# MB9BF56xM register map
Vendor: Cypress; File version: 2.1
CPU: CM4 r0p1, little endian, MPU, FPU, 4 interrupt priority bits
Registers are 32-bit, read-write, reset 0x0 unless marked. A register's access mark holds for its fields unless they carry their own. Offsets are from the block's base; [hi:lo] are bit positions; {n}, {i} and the like mark numbered series; 'fields as' and 'values as' point back to an identical list.

## CAN0 — CAN0 Registers
Base 0x40062000
Same registers: CAN1 0x40063000
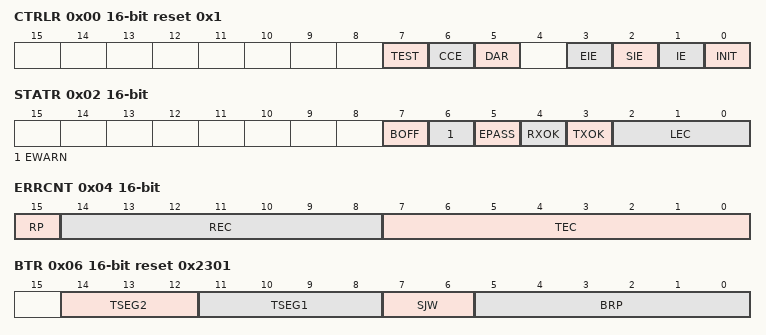
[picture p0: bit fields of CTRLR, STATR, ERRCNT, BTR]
0x00 CTRLR 16-bit reset 0x1 — CAN Control Register [BHW]
  [7] TEST — Test mode enable bit
  [6] CCE — Bit Timing Register write enable bit
  [5] DAR — Automatic retransmission disable bit
  [3] EIE — Error interrupt code enable bit
  [2] SIE — Status interrupt code enable bit
  [1] IE — Interrupt enable bit
  [0] INIT — Initialization bit
0x02 STATR 16-bit — CAN Status Register [BHW]
  [7] BOFF ro — Busoff bit
  [6] EWARN ro — Warning bit
  [5] EPASS ro — Error passive bit
  [4] RXOK — Successful message reception bit
  [3] TXOK — Successful message transmission bit
  [2:0] LEC — Last error code bits
0x04 ERRCNT 16-bit ro — CAN Error Counter [BHW]
  [15] RP — Receive error passive indication
  [14:8] REC — Receive error counter
  [7:0] TEC — Send error counter
0x06 BTR 16-bit reset 0x2301 — CAN Bit Timing Register [BHW]
  [14:12] TSEG2 — Time segment 2 setting bits
  [11:8] TSEG1 — Time segment 1 setting bits
  [7:6] SJW — Resynchronization jump width setting bits
  [5:0] BRP — Baud rate prescaler setting bits
0x08 INTR 16-bit ro — CAN Interrupt Register [BHW]
  [15:0] INTID — Interrupt Code
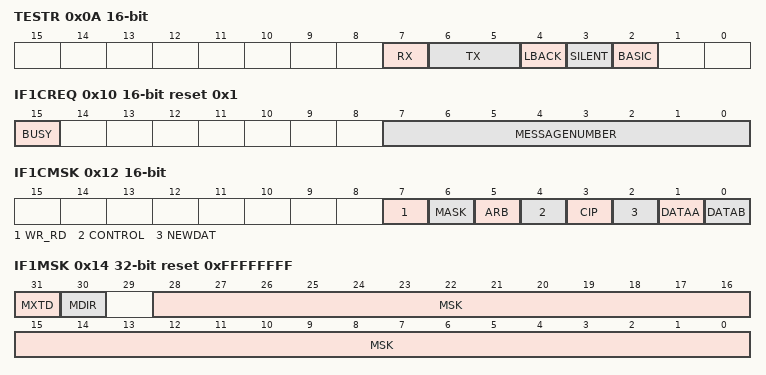
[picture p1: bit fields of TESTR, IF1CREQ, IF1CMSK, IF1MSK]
0x0A TESTR 16-bit — CAN Test Register [BHW]
  [7] RX ro — Rx pin monitor bit
  [6:5] TX — TX pin control bit
  [4] LBACK — Loop back mode
  [3] SILENT — Silent mode
  [2] BASIC — Basic mode
0x0C BRPER 16-bit — CAN Prescaler Extension Register [BHW]
  [3:0] BRPE — Baud rate prescaler extension bit
0x10 IF1CREQ 16-bit reset 0x1 — IF1 Command Request Register [BHW]
  [15] BUSY — Busy flag bit
  [7:0] MESSAGENUMBER
0x12 IF1CMSK 16-bit — IF1 Command Mask Register [BHW]
  [7] WR_RD — Writing or reading control bit
  [6] MASK — Mask data update bit
  [5] ARB — Arbitration data update bit
  [4] CONTROL — Control data update bit
  [3] CIP — Interrupt clear bit
  [2] NEWDAT — Message transmission request bit
  [1] DATAA — Data 0-3 update bit
  [0] DATAB — Data 4-7 update bit
0x14 IF1MSK reset 0xFFFFFFFF — IF1 Mask Registers [BHW]
  [31] MXTD, [30] MDIR, [28:0] MSK
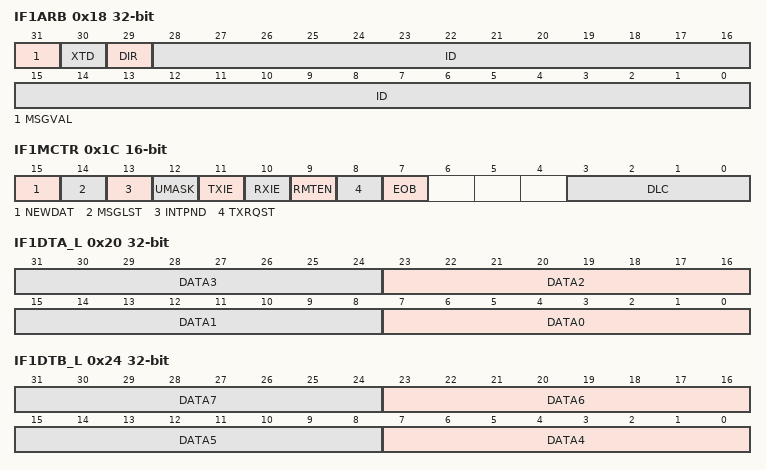
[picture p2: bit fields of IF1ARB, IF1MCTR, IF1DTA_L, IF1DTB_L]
0x18 IF1ARB — IF1 Arbitration Registers [BHW]
  [31] MSGVAL, [30] XTD, [29] DIR, [28:0] ID
0x1C IF1MCTR 16-bit — IF1 Message Control Register [BHW]
  [15] NEWDAT, [14] MSGLST, [13] INTPND, [12] UMASK, [11] TXIE, [10] RXIE, [9] RMTEN, [8] TXRQST, [7] EOB, [3:0] DLC
0x20 IF1DTA_L — IF1 Data Registers A [BHW]
  [8n+7:8n] DATA{n} (n=0..3) — Data({n}) Little Endian
0x24 IF1DTB_L — IF1 Data Registers B [BHW]
  [8n-25:8n-32] DATA{n} (n=4..7) — Data({n}) Little Endian
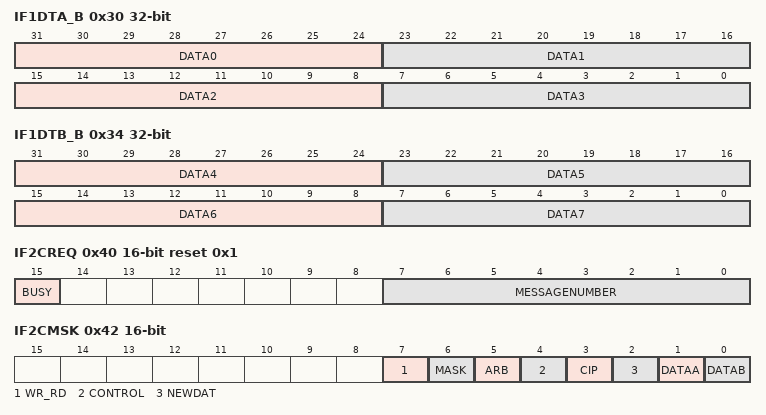
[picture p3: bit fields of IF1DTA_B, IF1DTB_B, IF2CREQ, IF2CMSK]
0x30 IF1DTA_B — IF1 Data Registers A [BHW]
  [31-8n:24-8n] DATA{n} (n=0..3) — Data({n}) Big Endian
0x34 IF1DTB_B — IF1 Data Registers B [BHW]
  [63-8n:56-8n] DATA{n} (n=4..7) — Data({n}) Big Endian
0x40 IF2CREQ 16-bit reset 0x1 — IF2 Command Request Register [BHW]
  [15] BUSY — Busy flag bit
  [7:0] MESSAGENUMBER
0x42 IF2CMSK 16-bit — IF2 Command Mask Register [BHW]
  fields as IF1CMSK
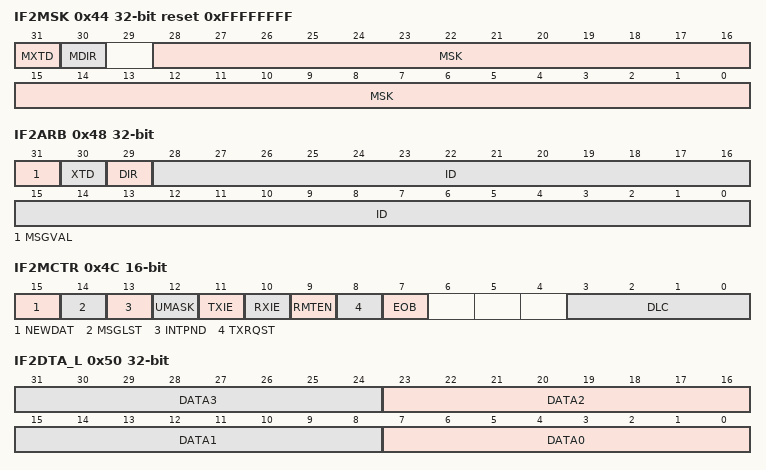
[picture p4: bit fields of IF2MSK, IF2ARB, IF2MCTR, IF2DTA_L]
0x44 IF2MSK reset 0xFFFFFFFF — IF2 Mask Registers [BHW]
  [31] MXTD, [30] MDIR, [28:0] MSK
0x48 IF2ARB — IF2 Arbitration Registers [BHW]
  [31] MSGVAL, [30] XTD, [29] DIR, [28:0] ID
0x4C IF2MCTR 16-bit — IF2 Message Control Register [BHW]
  fields as IF1MCTR
0x50 IF2DTA_L — IF2 Data Registers A [BHW]
  [8n+7:8n] DATA{n} (n=0..3) — Data({n}) Little Endian
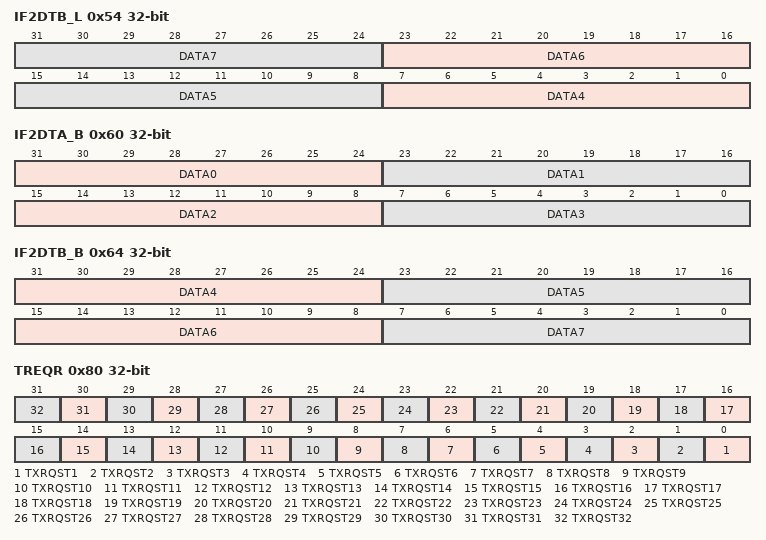
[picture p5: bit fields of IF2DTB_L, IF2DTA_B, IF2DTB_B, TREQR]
0x54 IF2DTB_L — IF2 Data Registers B [BHW]
  [8n-25:8n-32] DATA{n} (n=4..7) — Data({n}) Little Endian
0x60 IF2DTA_B — IF2 Data Registers A [BHW]
  [31-8n:24-8n] DATA{n} (n=0..3) — Data({n}) Big Endian
0x64 IF2DTB_B — IF2 Data Registers B [BHW]
  [63-8n:56-8n] DATA{n} (n=4..7) — Data({n}) Big Endian
0x80 TREQR ro — CAN Transmit Request Registers [BHW]
  [n-1] TXRQST{n} (n=1..32) — Bit{n-1} of TREQR
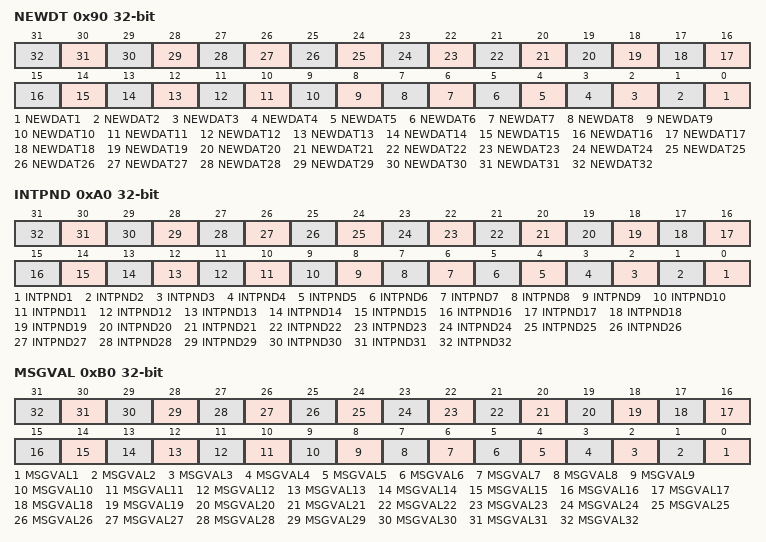
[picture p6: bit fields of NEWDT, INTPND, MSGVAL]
0x90 NEWDT ro — CAN New Data Registers [BHW]
  [n-1] NEWDAT{n} (n=1..32) — Bit{n-1} of NEWDT
0xA0 INTPND ro — CAN Interrupt Pending Registers [BHW]
  [n-1] INTPND{n} (n=1..32) — Bit{n-1} of INTPND
0xB0 MSGVAL ro — CAN Message Valid Register [BHW]
  [n-1] MSGVAL{n} (n=1..32) — Bit{n-1} of MSGVAL

## Notices in the file
Copyright (C) 2013-2016, Cypress Semiconductor Corporation or a
subsidiary of Cypress Semiconductor Corporation.  All rights reserved.
This software, including source code, documentation and related
materials ("Software"), is owned by Cypress Semiconductor Corporation or
one of its subsidiaries ("Cypress") and is protected by and subject to
worldwide patent protection (United States and foreign), United States
copyright laws and international treaty provisions. Therefore, you may use
this Software only as provided in the license agreement accompanying the
software package from which you obtained this Software ("EULA").
If no EULA applies, Cypress hereby grants you a personal, non-exclusive,
non-transferable license to copy, modify, and compile the
Software source code solely for use in connection with Cypress's
integrated circuit products.  Any reproduction, modification, translation,
compilation, or representation of this Software except as specified
above is prohibited without the express written permission of Cypress.
Disclaimer: THIS SOFTWARE IS PROVIDED AS-IS, WITH NO
WARRANTY OF ANY KIND, EXPRESS OR IMPLIED, INCLUDING,
BUT NOT LIMITED TO, NONINFRINGEMENT, IMPLIED
WARRANTIES OF MERCHANTABILITY AND FITNESS FOR A
PARTICULAR PURPOSE. Cypress reserves the right to make
changes to the Software without notice. Cypress does not assume any
liability arising out of the application or use of the Software or any
product or circuit described in the Software. Cypress does not
authorize its products for use in any products where a malfunction or
failure of the Cypress product may reasonably be expected to result in
significant property damage, injury or death ("High Risk Product"). By
including Cypress's product in a High Risk Product, the manufacturer
of such system or application assumes all risk of such use and in doing
so agrees to indemnify Cypress against all liability.
